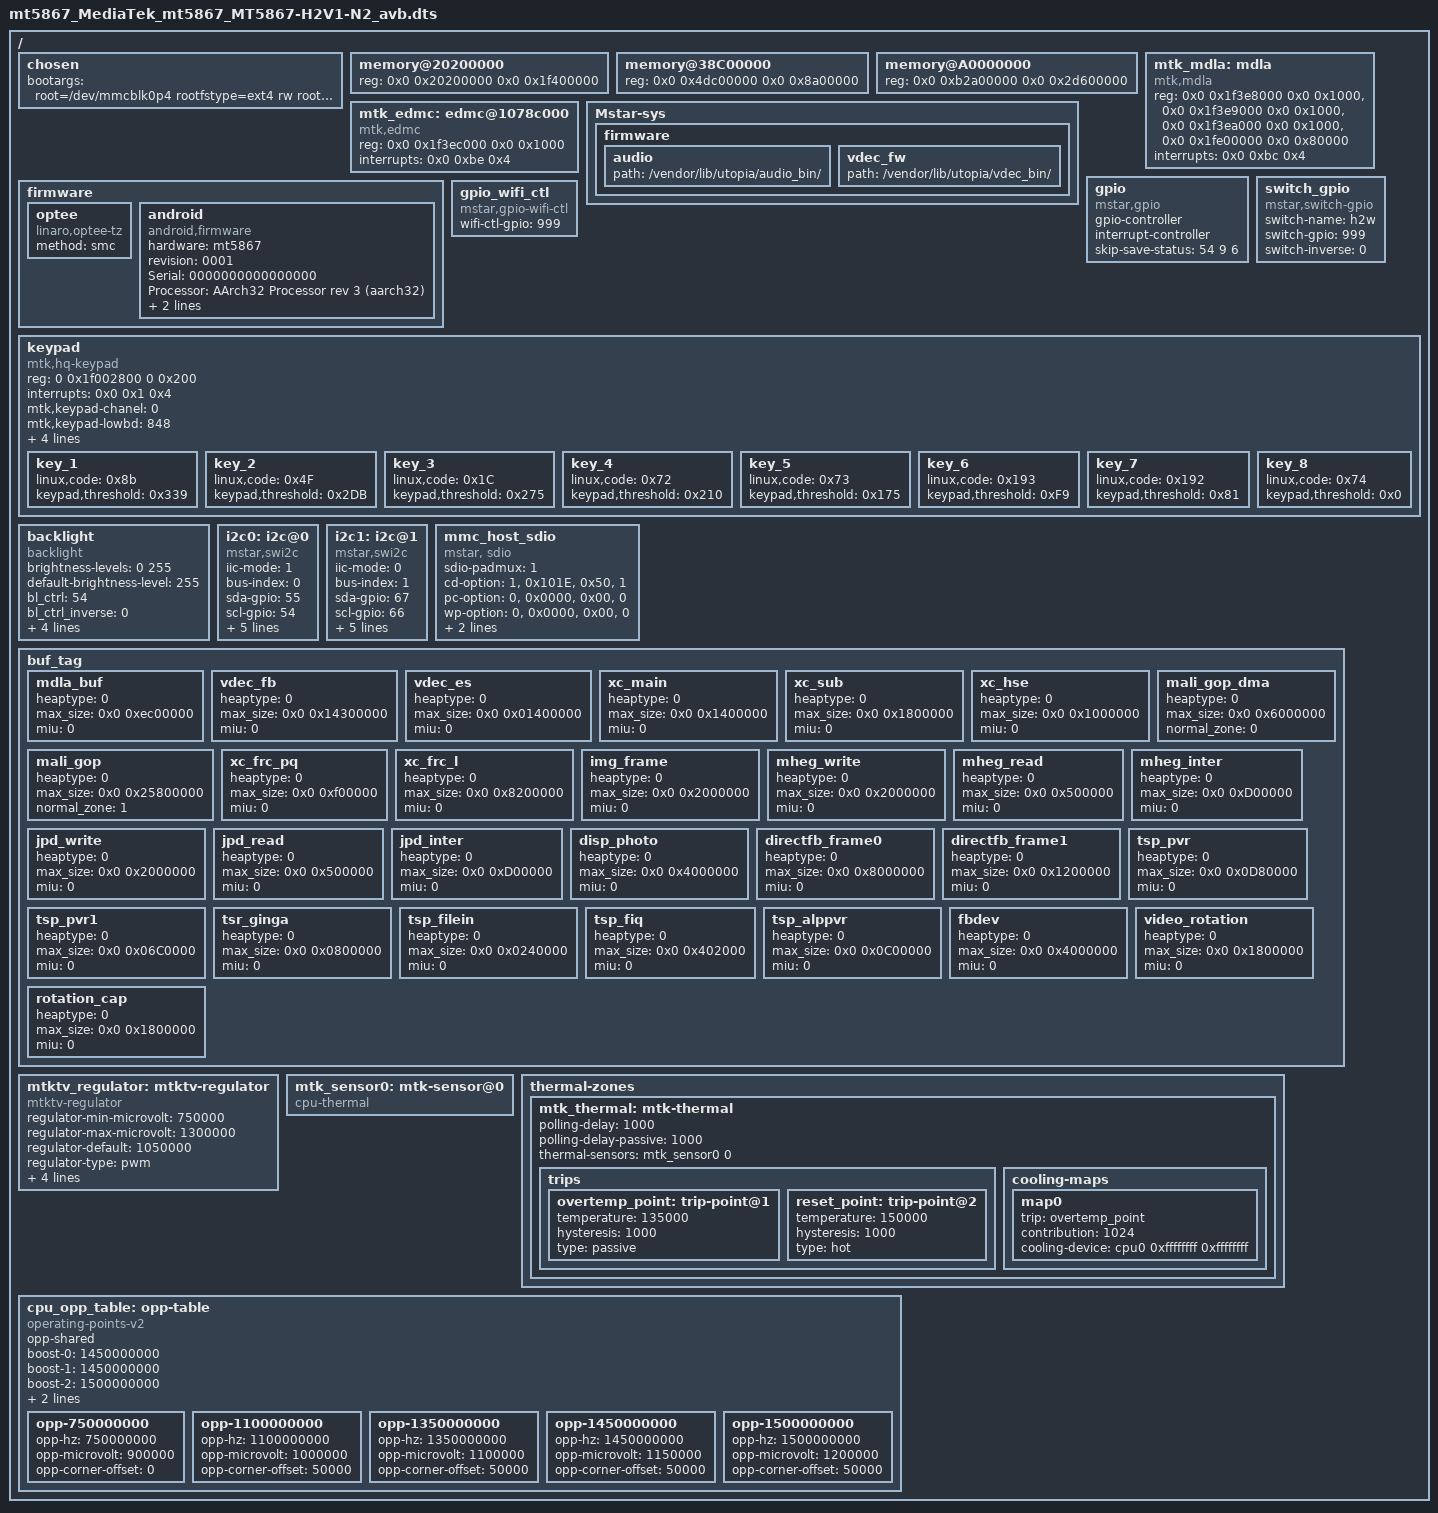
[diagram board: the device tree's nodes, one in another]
/*
 * ARM Ltd.
 *
 * ARMv8 Foundation model DTS
 */
#include "../../../../drivers/mstar2/hal/mt5867/gpio/mhal_gpio_reg.h"
/dts-v1/;
#include "mt5867.dtsi"

/ {

	chosen {
		bootargs = "root=/dev/mmcblk0p4 rootfstype=ext4 rw rootwait init=/sbin/init ip=dhcp console=ttyS0,115200,LX_MEM=0x02000000";
	};

	memory@20200000 {
		device_type = "memory";
		reg = <0x0 0x20200000 0x0 0x1f400000>;
	};

	memory@38C00000 {
		device_type = "memory";
		reg = <0x0 0x4dc00000 0x0 0x8a00000>;
	};

	memory@A0000000 {
		device_type = "memory";
		reg = <0x0 0xb2a00000 0x0 0x2d600000>;
	};

	mtk_mdla: mdla {
		  compatible = "mtk,mdla";
		  reg =   <0x0 0x1f3e8000 0x0 0x1000>,
		      <0x0 0x1f3e9000 0x0 0x1000>,
		      <0x0 0x1f3ea000 0x0 0x1000>,
		      <0x0 0x1fe00000 0x0 0x80000>;
		  interrupts = <0x0 0xbc 0x4>;
	};

	mtk_edmc: edmc@1078c000 {
		  compatible = "mtk,edmc";
		  reg = <0x0 0x1f3ec000 0x0 0x1000>;
		  interrupts = <0x0 0xbe 0x4>;
	};

	Mstar-sys {
		firmware {
			audio {
				path = "/vendor/lib/utopia/audio_bin/";
			};
			vdec_fw {
				path = "/vendor/lib/utopia/vdec_bin/";
			};
		};
	};


	firmware {
                optee {
                        compatible = "linaro,optee-tz";
                        method = "smc";
                };
		android {
			compatible = "android,firmware";
			hardware ="mt5867";
			revision ="0001";
			Serial   ="0000000000000000";
			Processor ="AArch32 Processor rev 3 (aarch32)";
			mode ="20170621";
			baseband ="20170621";
		};
	};

	/* example of consume a gpio pin with mapped irq
	foo{
		interrupt-parent = <&gpio>;
		interrupts = <0 LEVEL_HIGH>;
	}
	*/

	gpio: gpio {
		compatible = "mstar,gpio";
		gpio-controller;
		#gpio-cells = <1>;
		interrupt-controller;
		skip-save-status = <54 9 6>;
		#interrupt-cells = <2>; /* cell name GPIO_PAD, trigger-type*/
	};

	switch_gpio: switch_gpio {
		compatible = "mstar,switch-gpio";
		switch-name = "h2w";
		switch-gpio = <999>;
		switch-inverse = <0>;
	};

	gpio_wifi_ctl: gpio_wifi_ctl: gpio_wifi_ctl {
		compatible = "mstar,gpio-wifi-ctl";
		wifi-ctl-gpio = <999>;
	};

        keypad: keypad {
                compatible = "mtk,hq-keypad";
                reg = <0 0x1f002800 0 0x200>;
                interrupts = <0x0 0x1 0x4>;
                mtk,keypad-chanel = <0>;
                mtk,keypad-lowbd = <848>;
                mtk,keypad-upwbd = <1023>;
                mtk,keypad-num = <8>;
                linux,input-no-autorepeat;
                wakeup-source;

                key_1 {
                        linux,code = <0x8b>;
                        keypad,threshold = <0x339>;
                };

                key_2 {
                        linux,code = <0x4F>;
                        keypad,threshold = <0x2DB>;
                };

                key_3 {
                        linux,code = <0x1C>;
                        keypad,threshold = <0x275>;
                };

                key_4 {
                        linux,code = <0x72>;
                        keypad,threshold = <0x210>;
                };

                key_5 {
                        linux,code = <0x73>;
                        keypad,threshold = <0x175>;
                };

                key_6 {
                        linux,code = <0x193>;
                        keypad,threshold = <0xF9>;
                };

                key_7 {
                        linux,code = <0x192>;
                        keypad,threshold = <0x81>;
                };

                key_8 {
                        linux,code = <0x74>;
                        keypad,threshold = <0x0>;
                };
        };

	backlight: backlight {
		compatible = "backlight";
		brightness-levels = <0 255>;
		default-brightness-level = <255>;
		bl_ctrl = <54>;
		bl_ctrl_inverse = <0>;
		vcc_gpio = <9>;
		vcc_gpio_invert = <0>;
		led_gpio = <6>;
		led_gpio_invert = <0>;
		/* led-pwm-control-support; */
		/* led-pwm-control-channel = <0>; */
		/* led-pwm-control-resume-period = <0xb71a>; */
		/* led-pwm-control-resume-duty = <0xb71a>; */
		/* led-pwm-control-resume-div = <0xff>; */
		/* led-pwm-control-resume-polarity = <0>; */
		/* led-pwm-control-suspend-period = <0xb71a>; */
		/* led-pwm-control-suspend-duty = <0xb71a>; */
		/* led-pwm-control-suspend-div = <0xff>; */
		/* led-pwm-control-suspend-polarity = <0>; */
	};

	i2c0: i2c@0 {
		compatible = "mstar,swi2c";
		iic-mode = <1>;	 /* i2c-mode: 0:swi2c; 1:hwi2c */
		bus-index = <0>;	/* swi2c setting: bus index */
		sda-gpio = <55>;	/* swi2c setting: sda pad */
		scl-gpio = <54>;	/* swi2c setting: scl pad */
		def-delay = <100>;  /* swi2c setting: clk */
		hw-port = <3>;	  /* hwi2c setting: port */
		pad-mux = <25>;	 /* hwi2c setting: pad mux */
		speed-khz = <100>;  /* hwi2c setting: clk */
		retries = <5>;	  /* Unused */
		status = "okay";	/* Unused */
	};


	i2c1: i2c@1 {
		compatible = "mstar,swi2c";
		iic-mode = <0>;
		bus-index = <1>;
		sda-gpio = <67>;
		scl-gpio = <66>;
		def-delay = <100>;
		hw-port = <0>;
		pad-mux = <0>;
		speed-khz = <100>;
		retries = <5>;
		status = "okay";
	};


	mmc_host_sdio {
		compatible = "mstar, sdio";
		sdio-padmux = <1>;
		cd-option = <1>,<0x101E>,<0x50>,<1>;
		pc-option = <0>,<0x0000>,<0x00>,<0>;
		wp-option = <0>,<0x0000>,<0x00>,<0>;
		sdio-volt-type = <0>;
		sdio-fast-connect = <0>;
	};

	buf_tag {
	/* heaptype: HEAP_TYPE_IOMMU = 0, HEAP_TYPE_CMA= 1,  HEAP_TYPE_NON_MMA = 2*/
	/* miutype:  UMA_OR_MIU0 = 0, MIU_1 = 1 */
		mdla_buf {
			heaptype = <0>;
			max_size = <0x0 0xec00000>;
			miu = <0>;
		};
		vdec_fb {
			heaptype = <0>;
			max_size = <0x0 0x14300000>;
			miu = <0>;
		};
		vdec_es {
			heaptype = <0>;
			max_size = <0x0 0x01400000>;
			miu = <0>;
		};
		xc_main {
			heaptype = <0>;
			max_size = <0x0 0x1400000>;
			miu = <0>;
		};
		xc_sub {
			heaptype = <0>;
			max_size = <0x0 0x1800000>;
			miu = <0>;
		};
		xc_hse {
			heaptype = <0>;
			max_size = <0x0 0x1000000>;
			miu = <0>;
		};
		mali_gop_dma {
			heaptype = <0>;
			max_size = <0x0 0x6000000>;
			normal_zone = <0>;
		};
		mali_gop {
			heaptype = <0>;
			max_size = <0x0 0x25800000>;
			normal_zone = <1>;
		};
		xc_frc_pq {
			heaptype = <0>;
			max_size = <0x0 0xf00000>;
			miu = <0>;
		};
		xc_frc_l {
			heaptype = <0>;
			max_size = <0x0 0x8200000>;
			miu = <0>;
		};
		img_frame {
			heaptype = <0>;
			max_size = <0x0 0x2000000>;
			miu = <0>;
		};
		mheg_write {
			heaptype = <0>;
			max_size = <0x0 0x2000000>;
			miu = <0>;
		};
		mheg_read {
			heaptype = <0>;
			max_size = <0x0 0x500000>;
			miu = <0>;
		};
		mheg_inter {
			heaptype = <0>;
			max_size = <0x0 0xD00000>;
			miu = <0>;
		};
		jpd_write {
			heaptype = <0>;
			max_size = <0x0 0x2000000>;
			miu = <0>;
		};
		jpd_read {
			heaptype = <0>;
			max_size = <0x0 0x500000>;
			miu = <0>;
		};
		jpd_inter {
			heaptype = <0>;
			max_size = <0x0 0xD00000>;
			miu = <0>;
		};
		disp_photo {
			heaptype = <0>;
			max_size = <0x0 0x4000000>;
			miu = <0>;
		};
		directfb_frame0 {
			heaptype = <0>;
			max_size = <0x0 0x8000000>;
			miu = <0>;
		};
		directfb_frame1 {
			heaptype = <0>;
			max_size = <0x0 0x1200000>;
			miu = <0>;
		};
		tsp_pvr {
			heaptype = <0>;
			max_size = <0x0 0x0D80000>;
			miu = <0>;
		};
		tsp_pvr1 {
			heaptype = <0>;
			max_size = <0x0 0x06C0000>;
			miu = <0>;
		};
        tsr_ginga {
             heaptype = <0>;
             max_size = <0x0 0x0800000>;
             miu = <0>;
         };
		tsp_filein {
			heaptype = <0>;
			max_size = <0x0 0x0240000>;
			miu = <0>;
		};
		tsp_fiq {
			heaptype = <0>;
			max_size = <0x0 0x402000>;
			miu = <0>;
		};
		tsp_alppvr {
			heaptype = <0>;
			max_size = <0x0 0x0C00000>;
			miu = <0>;
		};
		fbdev {
			heaptype = <0>;
			max_size = <0x0 0x4000000>;
			miu = <0>;
		};
        video_rotation {
			heaptype = <0>;
			max_size = <0x0 0x1800000>;
			miu = <0>;
		};
		rotation_cap {
			heaptype = <0>;
			max_size = <0x0 0x1800000>;
			miu = <0>;
		};
	};

	mtktv_regulator: mtktv-regulator {
		compatible = "mtktv-regulator";
		regulator-min-microvolt = <750000>;
		regulator-max-microvolt = <1300000>;
		regulator-default = <1050000>;

		/* prado regulator */
		/*
		regulator-type = "prado";
		regulator-id = <0x9A>;
		regulator-step = <3>;
		regulator-shift = <68>;
		regulator-port = <3>;
		regulator-addr = <0x80>;
		*/
		/* pwm regulator */
		regulator-type = "pwm";
		regulator-channel = <0>;
		regulator-scale = <1950>;
		regulator-offset = <0>;
		regulator-auto = <1>;
		/* gpio regulator */
		/*
		regulator-type = "gpio";
		regulator-level = <2>;
		regulator-parm {
			control_0 {
				power = <95>;
				pins = <2>;
				gpio_num = <51 52>;
				gpio_mode = <0 1>;
			};
			control_1 {
				power = <100>;
				pins = <2>;
				gpio_num = <51 52>;
				gpio_mode = <1 1>;
			};
		};
		*/
	};

	mtk_sensor0: mtk-sensor@0 {
		compatible = "cpu-thermal";
		#thermal-sensor-cells = <1>;
	};

	thermal-zones {
		mtk_thermal: mtk-thermal {
			polling-delay = <1000>;
			polling-delay-passive = <1000>;

			thermal-sensors = <&mtk_sensor0 0>;
			trips {
				overtemp_point: trip-point@1 {
					temperature = <135000>; /* millicelsius */
					hysteresis = <1000>; /* millicelsius */
					type = "passive";
				};
				reset_point: trip-point@2 {
					temperature = <150000>; /* millicelsius */
					hysteresis = <1000>; /* millicelsius */
					type = "hot";
				};
			};
			cooling-maps {
				map0 {
					trip = <&overtemp_point>;
					contribution = <1024>;
					cooling-device = <&cpu0 0xffffffff 0xffffffff>;
				};

			};
		};
	};

	cpu_opp_table: opp-table {
		compatible = "operating-points-v2";
		opp-shared;

		boost-0 = <1450000000>;
		boost-1 = <1450000000>;
		boost-2 = <1500000000>;
		boost-3 = <1450000000>;
		boost-4 = <1450000000>;

		opp-750000000 {
			opp-hz = /bits/ 64 <750000000>;
			opp-microvolt = <900000>;
			opp-corner-offset = <0>;
		};

		opp-1100000000 {
			opp-hz = /bits/ 64 <1100000000>;
			opp-microvolt = <1000000>;
			opp-corner-offset = <50000>;
		};

		opp-1350000000 {
			opp-hz = /bits/ 64 <1350000000>;
			opp-microvolt = <1100000>;
			opp-corner-offset = <50000>;
		};

		opp-1450000000 {
			opp-hz = /bits/ 64 <1450000000>;
			opp-microvolt = <1150000>;
			opp-corner-offset = <50000>;
		};

		opp-1500000000 {
			opp-hz = /bits/ 64 <1500000000>;
			opp-microvolt = <1200000>;
			opp-corner-offset = <50000>;
		};

	};
};
